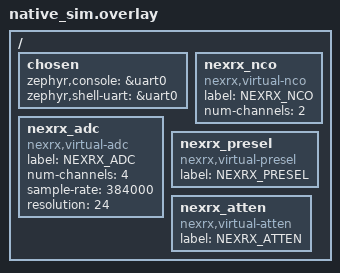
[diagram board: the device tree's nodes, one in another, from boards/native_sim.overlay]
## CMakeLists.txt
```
# SPDX-License-Identifier: MIT
# NexRx Digital Twin - Zephyr Firmware for native_sim
#
# This builds the STM32 firmware to run on Linux x86_64 for
# software-in-the-loop testing with the Xyce RF simulation.

cmake_minimum_required(VERSION 3.20.0)

find_package(Zephyr REQUIRED HINTS $ENV{ZEPHYR_BASE})
project(nexrx_twin_fw)

# C++20 for firmware
target_compile_features(app PRIVATE cxx_std_20)

# Main application sources
target_sources(app PRIVATE
    src/main.cpp
    src/twin_transport.cpp
    src/virtual_nco.cpp
    src/virtual_adc.cpp
)

# Include paths
target_include_directories(app PRIVATE
    ${CMAKE_CURRENT_SOURCE_DIR}/src
    ${CMAKE_CURRENT_SOURCE_DIR}/../src  # Access twin headers (IQFrame, etc.)
)
```

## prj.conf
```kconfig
# SPDX-License-Identifier: MIT
# NexRx Digital Twin - Zephyr Configuration for native_sim

# C++ Support
CONFIG_CPP=y
CONFIG_STD_CPP20=y
CONFIG_PICOLIBC=y

# Console and Logging
CONFIG_SERIAL=y
CONFIG_UART_CONSOLE=y
CONFIG_CONSOLE=y
CONFIG_LOG=y
CONFIG_LOG_MODE_IMMEDIATE=y
CONFIG_LOG_DEFAULT_LEVEL=3

# POSIX API for native_sim
CONFIG_POSIX_API=y
CONFIG_POSIX_SHARED_MEMORY_OBJECTS=y
CONFIG_POSIX_MEMORY_PROTECTION=y

# Threading
CONFIG_MAIN_STACK_SIZE=8192
CONFIG_SYSTEM_WORKQUEUE_STACK_SIZE=4096

# Heap for dynamic allocation
CONFIG_HEAP_MEM_POOL_SIZE=65536

# Enable shell for debugging
CONFIG_SHELL=y
CONFIG_SHELL_BACKEND_SERIAL=y

# Timer for simulation timing
CONFIG_SYS_CLOCK_TICKS_PER_SEC=1000
```

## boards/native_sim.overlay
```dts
/*
 * SPDX-License-Identifier: MIT
 * NexRx Digital Twin - Device Tree Overlay for native_sim
 *
 * Defines virtual peripherals that map to the twin simulation.
 */

/ {
    chosen {
        zephyr,console = &uart0;
        zephyr,shell-uart = &uart0;
    };

    /* Virtual NCO control interface */
    nexrx_nco: nexrx_nco {
        compatible = "nexrx,virtual-nco";
        label = "NEXRX_NCO";
        status = "okay";
        /* Two NCO channels for dual-OSD */
        num-channels = <2>;
    };

    /* Virtual ADC interface (I/Q from simulation) */
    nexrx_adc: nexrx_adc {
        compatible = "nexrx,virtual-adc";
        label = "NEXRX_ADC";
        status = "okay";
        /* 4 channels: I0, Q0, I1, Q1 */
        num-channels = <4>;
        sample-rate = <384000>;
        resolution = <24>;
    };

    /* Virtual preselector control */
    nexrx_presel: nexrx_presel {
        compatible = "nexrx,virtual-presel";
        label = "NEXRX_PRESEL";
        status = "okay";
    };

    /* Virtual attenuator control */
    nexrx_atten: nexrx_atten {
        compatible = "nexrx,virtual-atten";
        label = "NEXRX_ATTEN";
        status = "okay";
    };
};
```

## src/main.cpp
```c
/*
 * SPDX-License-Identifier: MIT
 * NexRx Digital Twin - Zephyr Firmware Main
 *
 * Entry point for the STM32 firmware running on native_sim.
 * Connects to the twin orchestrator for I/Q data and control.
 *
 * Copyright 2026 NexRx Project
 */

#include <zephyr/kernel.h>
#include <zephyr/logging/log.h>
#include <zephyr/shell/shell.h>
#include <inttypes.h>
#include <stdlib.h>

#include "twin_transport.hpp"
#include "virtual_nco.hpp"
#include "virtual_adc.hpp"

LOG_MODULE_REGISTER(nexrx_main, LOG_LEVEL_INF);

namespace {

// Twin transport for communication with orchestrator
nexrx::TwinTransport g_transport;

// Virtual peripherals
nexrx::VirtualNco g_nco;
nexrx::VirtualAdc g_adc;

// Current VFO frequencies (Hz)
uint64_t g_vfo_freq[3] = {14000000, 14000000, 14000000};

// Processing thread
K_THREAD_STACK_DEFINE(process_stack, 4096);
struct k_thread process_thread;

void process_iq_thread(void* p1, void* p2, void* p3) {
    ARG_UNUSED(p1);
    ARG_UNUSED(p2);
    ARG_UNUSED(p3);

    LOG_INF("I/Q processing thread started");

    while (true) {
        // Read I/Q frame from shared memory
        if (g_adc.hasData()) {
            auto frame = g_adc.readFrame();

            // Process I/Q data here
            // In real firmware, this would:
            // 1. Apply digital filtering
            // 2. Combine OSD outputs for image rejection
            // 3. Decimate to audio rate
            // 4. Send to USB audio class

            // For now, just count frames
            static uint64_t frame_count = 0;
            if (++frame_count % 9600 == 0) {  // Every 100ms
                LOG_INF("Processed %" PRIu64 " frames", frame_count);
            }
        } else {
            // No data available, sleep briefly
            k_msleep(1);
        }
    }
}

} // anonymous namespace

// Shell commands for debugging
static int cmd_status(const struct shell* sh, size_t argc, char** argv) {
    ARG_UNUSED(argc);
    ARG_UNUSED(argv);

    shell_print(sh, "NexRx Twin Firmware Status");
    shell_print(sh, "  Transport: %s", g_transport.isConnected() ? "connected" : "disconnected");
    shell_print(sh, "  VFO0: %" PRIu64 " Hz", g_vfo_freq[0]);
    shell_print(sh, "  VFO1: %" PRIu64 " Hz", g_vfo_freq[1]);
    shell_print(sh, "  VFO2: %" PRIu64 " Hz", g_vfo_freq[2]);
    shell_print(sh, "  ADC frames: %" PRIu64 "", g_adc.frameCount());

    return 0;
}

static int cmd_freq(const struct shell* sh, size_t argc, char** argv) {
    if (argc < 3) {
        shell_print(sh, "Usage: freq <vfo 0-2> <freq_hz>");
        return -EINVAL;
    }

    int vfo = atoi(argv[1]);
    uint64_t freq = strtoull(argv[2], nullptr, 10);

    if (vfo < 0 || vfo > 2) {
        shell_print(sh, "Invalid VFO: %d (must be 0-2)", vfo);
        return -EINVAL;
    }

    g_vfo_freq[vfo] = freq;
    g_nco.setFrequency(vfo, freq);

    shell_print(sh, "VFO%d set to %" PRIu64 " Hz", vfo, freq);
    return 0;
}

SHELL_STATIC_SUBCMD_SET_CREATE(nexrx_cmds,
    SHELL_CMD(status, NULL, "Show firmware status", cmd_status),
    SHELL_CMD(freq, NULL, "Set VFO frequency", cmd_freq),
    SHELL_SUBCMD_SET_END
);
SHELL_CMD_REGISTER(nexrx, &nexrx_cmds, "NexRx commands", NULL);

int main(void) {
    LOG_INF("NexRx Digital Twin Firmware starting...");
    LOG_INF("Build: %s %s", __DATE__, __TIME__);

    // Initialize transport to orchestrator
    if (!g_transport.initialize("/nexrx_iq", "/tmp/nexrx_rpc.sock")) {
        LOG_ERR("Failed to initialize transport");
        // Continue anyway - we can still test shell commands
    }

    // Initialize virtual peripherals
    g_nco.initialize(&g_transport);
    g_adc.initialize(&g_transport);

    // Set default frequencies
    for (int i = 0; i < 3; ++i) {
        g_nco.setFrequency(i, g_vfo_freq[i]);
    }

    // Start I/Q processing thread
    k_thread_create(&process_thread, process_stack,
                    K_THREAD_STACK_SIZEOF(process_stack),
                    process_iq_thread, nullptr, nullptr, nullptr,
                    K_PRIO_COOP(7), 0, K_NO_WAIT);
    k_thread_name_set(&process_thread, "iq_process");

    LOG_INF("Firmware initialized, entering shell");

    // Main thread just runs the shell
    // The processing happens in the process_iq_thread
    return 0;
}
```

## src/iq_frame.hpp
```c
/*
 * SPDX-License-Identifier: MIT
 * NexRx Digital Twin - I/Q Frame for Zephyr Firmware
 *
 * Standalone IQFrame definition without std library dependencies.
 * Must match the layout of transport/IQFrame.hpp exactly.
 *
 * For firmware (consumer side), we use volatile for the shared positions
 * since C++ doesn't support C11 _Atomic. The memory ordering is handled
 * by the orchestrator (producer) using proper atomics.
 *
 * Copyright 2026 NexRx Project
 */

#pragma once

#include <stdint.h>
#include <stddef.h>

/* I/Q Sample - single channel */
struct IQSample {
    int32_t i;  /* In-phase (24-bit signed) */
    int32_t q;  /* Quadrature (24-bit signed) */
};

/* I/Q Frame - one sample from dual OSDs */
struct IQFrame {
    struct IQSample osd[2];  /* OSD0, OSD1 */
    uint64_t timestamp_ns;   /* Simulation timestamp */
    uint32_t sequence;       /* Frame sequence number */
    uint32_t flags;          /* Status flags */
};

/* Ring buffer header - must match SharedMemTransport layout */
struct IQRingBufferHeader {
    uint32_t magic;          /* 0x4E455852 = "NEXR" */
    uint32_t version;
    uint32_t capacity;
    uint32_t frame_size;
    char padding1[48];       /* Align to 64 bytes */

    volatile uint64_t write_pos;  /* Producer position */
    char padding2[56];       /* Cache line padding */

    volatile uint64_t read_pos;   /* Consumer position */
    char padding3[56];

    volatile uint64_t overruns;
    volatile uint64_t underruns;
    volatile uint64_t write_count;
    volatile uint64_t read_count;
    char padding4[32];
};

#define IQ_RING_MAGIC 0x4E455852
#define IQ_RING_VERSION 1
```

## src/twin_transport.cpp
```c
/*
 * SPDX-License-Identifier: MIT
 * NexRx Digital Twin - Transport Implementation for Zephyr Firmware
 *
 * Simplified transport using only POSIX shared memory for I/Q data.
 * RPC functionality is stubbed out for now since Zephyr's native_sim
 * doesn't include Unix domain sockets in its POSIX layer.
 *
 * Copyright 2026 NexRx Project
 */

#include "twin_transport.hpp"

#include <zephyr/logging/log.h>
#include <zephyr/posix/sys/mman.h>
#include <zephyr/posix/fcntl.h>
#include <zephyr/posix/unistd.h>
#include <zephyr/posix/sys/stat.h>

#include <string.h>
#include <stdio.h>
#include <inttypes.h>
#include <errno.h>

LOG_MODULE_REGISTER(twin_transport, LOG_LEVEL_INF);

namespace nexrx {

TwinTransport::~TwinTransport() {
    shutdown();
}

bool TwinTransport::initialize(const char* shm_name, const char* rpc_path) {
    (void)rpc_path;  // RPC not implemented yet

    LOG_INF("Initializing twin transport");
    LOG_INF("  SHM: %s", shm_name);

    // Open shared memory for I/Q data
    shm_fd_ = shm_open(shm_name, O_RDONLY, 0);
    if (shm_fd_ < 0) {
        LOG_WRN("Failed to open shared memory: %s (errno=%d)", shm_name, errno);
        // Not fatal - orchestrator might not be running yet
        return false;
    }

    // Get size via fstat
    struct stat st;
    if (fstat(shm_fd_, &st) != 0) {
        LOG_ERR("Failed to stat shared memory");
        close(shm_fd_);
        shm_fd_ = -1;
        return false;
    }

    shm_size_ = st.st_size;
    shm_ptr_ = mmap(NULL, shm_size_, PROT_READ, MAP_SHARED, shm_fd_, 0);

    if (shm_ptr_ == MAP_FAILED) {
        LOG_ERR("Failed to mmap shared memory (errno=%d)", errno);
        close(shm_fd_);
        shm_fd_ = -1;
        shm_ptr_ = NULL;
        return false;
    }

    ring_header_ = static_cast<struct IQRingBufferHeader*>(shm_ptr_);
    ring_frames_ = reinterpret_cast<struct IQFrame*>(
        static_cast<uint8_t*>(shm_ptr_) + sizeof(struct IQRingBufferHeader));

    // Validate magic
    if (ring_header_->magic != IQ_RING_MAGIC) {
        LOG_ERR("Invalid shared memory magic: 0x%08x (expected 0x%08x)",
                ring_header_->magic, IQ_RING_MAGIC);
        munmap(shm_ptr_, shm_size_);
        close(shm_fd_);
        shm_fd_ = -1;
        shm_ptr_ = NULL;
        return false;
    }

    // Sync read position with current write position
    local_read_pos_ = ring_header_->read_pos;

    shm_connected_ = true;
    LOG_INF("Shared memory connected: %zu bytes, %u capacity",
            shm_size_, ring_header_->capacity);

    return true;
}

void TwinTransport::shutdown() {
    if (shm_ptr_ && shm_ptr_ != MAP_FAILED) {
        munmap(shm_ptr_, shm_size_);
        shm_ptr_ = NULL;
    }

    if (shm_fd_ >= 0) {
        close(shm_fd_);
        shm_fd_ = -1;
    }

    shm_connected_ = false;
    rpc_connected_ = false;
    ring_header_ = NULL;
    ring_frames_ = NULL;
}

bool TwinTransport::hasIqData() const {
    if (!shm_connected_ || !ring_header_) {
        return false;
    }

    uint64_t write_pos = ring_header_->write_pos;
    return write_pos != local_read_pos_;
}

bool TwinTransport::readIqFrame(struct IQFrame& frame) {
    if (!hasIqData()) {
        return false;
    }

    uint64_t write_pos = ring_header_->write_pos;

    if (local_read_pos_ == write_pos) {
        return false;
    }

    // Read frame from ring buffer
    size_t idx = local_read_pos_ % ring_header_->capacity;
    frame = ring_frames_[idx];

    // Advance read position
    ++local_read_pos_;

    return true;
}

size_t TwinTransport::availableFrames() const {
    if (!shm_connected_ || !ring_header_) {
        return 0;
    }

    uint64_t write_pos = ring_header_->write_pos;

    if (write_pos >= local_read_pos_) {
        return write_pos - local_read_pos_;
    }

    // Handle wrap (shouldn't happen with 64-bit counters)
    return 0;
}

bool TwinTransport::sendSetFrequency(int channel, uint64_t freq_hz) {
    (void)channel;
    (void)freq_hz;
    // RPC not implemented yet - would need Unix sockets or other IPC
    LOG_WRN("sendSetFrequency: RPC not implemented");
    return false;
}

bool TwinTransport::sendSetPreselector(uint16_t cap_mask, bool l701_short) {
    (void)cap_mask;
    (void)l701_short;
    LOG_WRN("sendSetPreselector: RPC not implemented");
    return false;
}

bool TwinTransport::sendSetAttenuator(uint8_t atten_db) {
    (void)atten_db;
    LOG_WRN("sendSetAttenuator: RPC not implemented");
    return false;
}

} // namespace nexrx
```

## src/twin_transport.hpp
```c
/*
 * SPDX-License-Identifier: MIT
 * NexRx Digital Twin - Transport Interface for Zephyr Firmware
 *
 * Provides communication with the twin orchestrator:
 * - Shared memory for I/Q data (high bandwidth)
 * - Unix socket for RPC control messages
 *
 * Copyright 2026 NexRx Project
 */

#pragma once

#include <stdint.h>
#include <stddef.h>

// Standalone IQFrame header for Zephyr (no std library deps)
#include "iq_frame.hpp"

namespace nexrx {

class TwinTransport {
public:
    TwinTransport() = default;
    ~TwinTransport();

    // Initialize transport connections
    // shm_name: POSIX shared memory name for I/Q data
    // rpc_path: Unix socket path for control RPC
    bool initialize(const char* shm_name, const char* rpc_path);

    // Shutdown connections
    void shutdown();

    // Check connection status
    bool isConnected() const { return shm_connected_ && rpc_connected_; }
    bool isShmConnected() const { return shm_connected_; }
    bool isRpcConnected() const { return rpc_connected_; }

    // I/Q Data Interface (via shared memory)
    bool hasIqData() const;
    bool readIqFrame(struct IQFrame& frame);
    size_t availableFrames() const;

    // RPC Interface (via Unix socket)
    bool sendSetFrequency(int channel, uint64_t freq_hz);
    bool sendSetPreselector(uint16_t cap_mask, bool l701_short);
    bool sendSetAttenuator(uint8_t atten_db);

private:
    // Shared memory state
    int shm_fd_ = -1;
    void* shm_ptr_ = nullptr;
    size_t shm_size_ = 0;
    bool shm_connected_ = false;

    // RPC socket state
    int rpc_fd_ = -1;
    bool rpc_connected_ = false;

    // Cached pointers into shared memory
    struct IQRingBufferHeader* ring_header_ = nullptr;
    struct IQFrame* ring_frames_ = nullptr;

    // Local read position (consumer side)
    uint64_t local_read_pos_ = 0;
};

} // namespace nexrx
```

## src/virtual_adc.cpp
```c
/*
 * SPDX-License-Identifier: MIT
 * NexRx Digital Twin - Virtual ADC Implementation
 *
 * Copyright 2026 NexRx Project
 */

#include "virtual_adc.hpp"
#include "twin_transport.hpp"

#include <zephyr/kernel.h>
#include <zephyr/logging/log.h>

LOG_MODULE_REGISTER(virtual_adc, LOG_LEVEL_INF);

namespace nexrx {

void VirtualAdc::initialize(TwinTransport* transport) {
    transport_ = transport;
    frame_count_ = 0;

    LOG_INF("Virtual ADC initialized");
    LOG_INF("  Channels: %d", NUM_CHANNELS);
    LOG_INF("  Sample rate: %u Hz", SAMPLE_RATE);
    LOG_INF("  Resolution: %d bits", RESOLUTION_BITS);
}

bool VirtualAdc::hasData() const {
    if (!transport_) {
        return false;
    }
    return transport_->hasIqData();
}

struct IQFrame VirtualAdc::readFrame() {
    struct IQFrame frame{};

    if (!transport_) {
        return frame;
    }

    // Block until data is available
    while (!transport_->hasIqData()) {
        k_msleep(1);
    }

    if (transport_->readIqFrame(frame)) {
        ++frame_count_;
    }

    return frame;
}

bool VirtualAdc::tryReadFrame(struct IQFrame& frame) {
    if (!transport_ || !transport_->hasIqData()) {
        return false;
    }

    if (transport_->readIqFrame(frame)) {
        ++frame_count_;
        return true;
    }

    return false;
}

size_t VirtualAdc::available() const {
    if (!transport_) {
        return 0;
    }
    return transport_->availableFrames();
}

} // namespace nexrx
```

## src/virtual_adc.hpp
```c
/*
 * SPDX-License-Identifier: MIT
 * NexRx Digital Twin - Virtual ADC Interface
 *
 * Replaces the physical ADC hardware in simulation.
 * Receives I/Q samples from the twin orchestrator via shared memory.
 *
 * Copyright 2026 NexRx Project
 */

#pragma once

#include <stdint.h>
#include <stddef.h>

#include "iq_frame.hpp"

namespace nexrx {

class TwinTransport;

class VirtualAdc {
public:
    static constexpr int NUM_CHANNELS = 4;  // I0, Q0, I1, Q1
    static constexpr uint32_t SAMPLE_RATE = 384000;
    static constexpr int RESOLUTION_BITS = 24;

    VirtualAdc() = default;

    // Initialize with transport to orchestrator
    void initialize(TwinTransport* transport);

    // Check if I/Q data is available
    bool hasData() const;

    // Read next I/Q frame (blocks if no data)
    struct IQFrame readFrame();

    // Read frame without blocking (returns false if no data)
    bool tryReadFrame(struct IQFrame& frame);

    // Get number of available frames
    size_t available() const;

    // Get total frame count since start
    uint64_t frameCount() const { return frame_count_; }

    // Get sample rate
    uint32_t sampleRate() const { return SAMPLE_RATE; }

    // Get resolution in bits
    int resolution() const { return RESOLUTION_BITS; }

private:
    TwinTransport* transport_ = nullptr;
    uint64_t frame_count_ = 0;
};

} // namespace nexrx
```

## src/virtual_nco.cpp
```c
/*
 * SPDX-License-Identifier: MIT
 * NexRx Digital Twin - Virtual NCO Implementation
 *
 * Copyright 2026 NexRx Project
 */

#include "virtual_nco.hpp"
#include "twin_transport.hpp"

#include <zephyr/logging/log.h>
#include <inttypes.h>

LOG_MODULE_REGISTER(virtual_nco, LOG_LEVEL_INF);

namespace nexrx {

void VirtualNco::initialize(TwinTransport* transport) {
    transport_ = transport;
    LOG_INF("Virtual NCO initialized with %d channels", NUM_CHANNELS);
}

bool VirtualNco::setFrequency(int channel, uint64_t freq_hz) {
    if (channel < 0 || channel >= NUM_CHANNELS) {
        LOG_ERR("Invalid NCO channel: %d", channel);
        return false;
    }

    freq_hz_[channel] = freq_hz;

    LOG_INF("NCO%d frequency set to %" PRIu64 " Hz", channel, freq_hz);

    // Send to orchestrator if connected
    if (transport_ && transport_->isRpcConnected()) {
        return transport_->sendSetFrequency(channel, freq_hz);
    }

    return true;
}

uint64_t VirtualNco::getFrequency(int channel) const {
    if (channel < 0 || channel >= NUM_CHANNELS) {
        return 0;
    }
    return freq_hz_[channel];
}

bool VirtualNco::setPhaseOffset(int channel, uint16_t phase_deg) {
    if (channel < 0 || channel >= NUM_CHANNELS) {
        return false;
    }

    phase_deg_[channel] = phase_deg % 360;

    LOG_INF("NCO%d phase offset set to %u deg", channel, phase_deg_[channel]);

    // Phase offset would be sent via RPC in a full implementation
    return true;
}

bool VirtualNco::setEnabled(int channel, bool enabled) {
    if (channel < 0 || channel >= NUM_CHANNELS) {
        return false;
    }

    enabled_[channel] = enabled;

    LOG_INF("NCO%d %s", channel, enabled ? "enabled" : "disabled");

    return true;
}

bool VirtualNco::isEnabled(int channel) const {
    if (channel < 0 || channel >= NUM_CHANNELS) {
        return false;
    }
    return enabled_[channel];
}

} // namespace nexrx
```

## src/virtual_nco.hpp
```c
/*
 * SPDX-License-Identifier: MIT
 * NexRx Digital Twin - Virtual NCO Interface
 *
 * Replaces the FPGA NCO hardware in simulation.
 * Sends frequency changes to the twin orchestrator which
 * updates the Xyce LO sources.
 *
 * Copyright 2026 NexRx Project
 */

#pragma once

#include <stdint.h>

namespace nexrx {

class TwinTransport;

class VirtualNco {
public:
    static constexpr int NUM_CHANNELS = 2;

    VirtualNco() = default;

    // Initialize with transport to orchestrator
    void initialize(TwinTransport* transport);

    // Set frequency for NCO channel (0-1)
    bool setFrequency(int channel, uint64_t freq_hz);

    // Get current frequency setting
    uint64_t getFrequency(int channel) const;

    // Set phase offset (for fine tuning)
    bool setPhaseOffset(int channel, uint16_t phase_deg);

    // Enable/disable NCO output
    bool setEnabled(int channel, bool enabled);

    // Check if NCO is enabled
    bool isEnabled(int channel) const;

private:
    TwinTransport* transport_ = nullptr;
    uint64_t freq_hz_[NUM_CHANNELS] = {14000000, 14000000};
    uint16_t phase_deg_[NUM_CHANNELS] = {0, 0};
    bool enabled_[NUM_CHANNELS] = {true, true};
};

} // namespace nexrx
```
